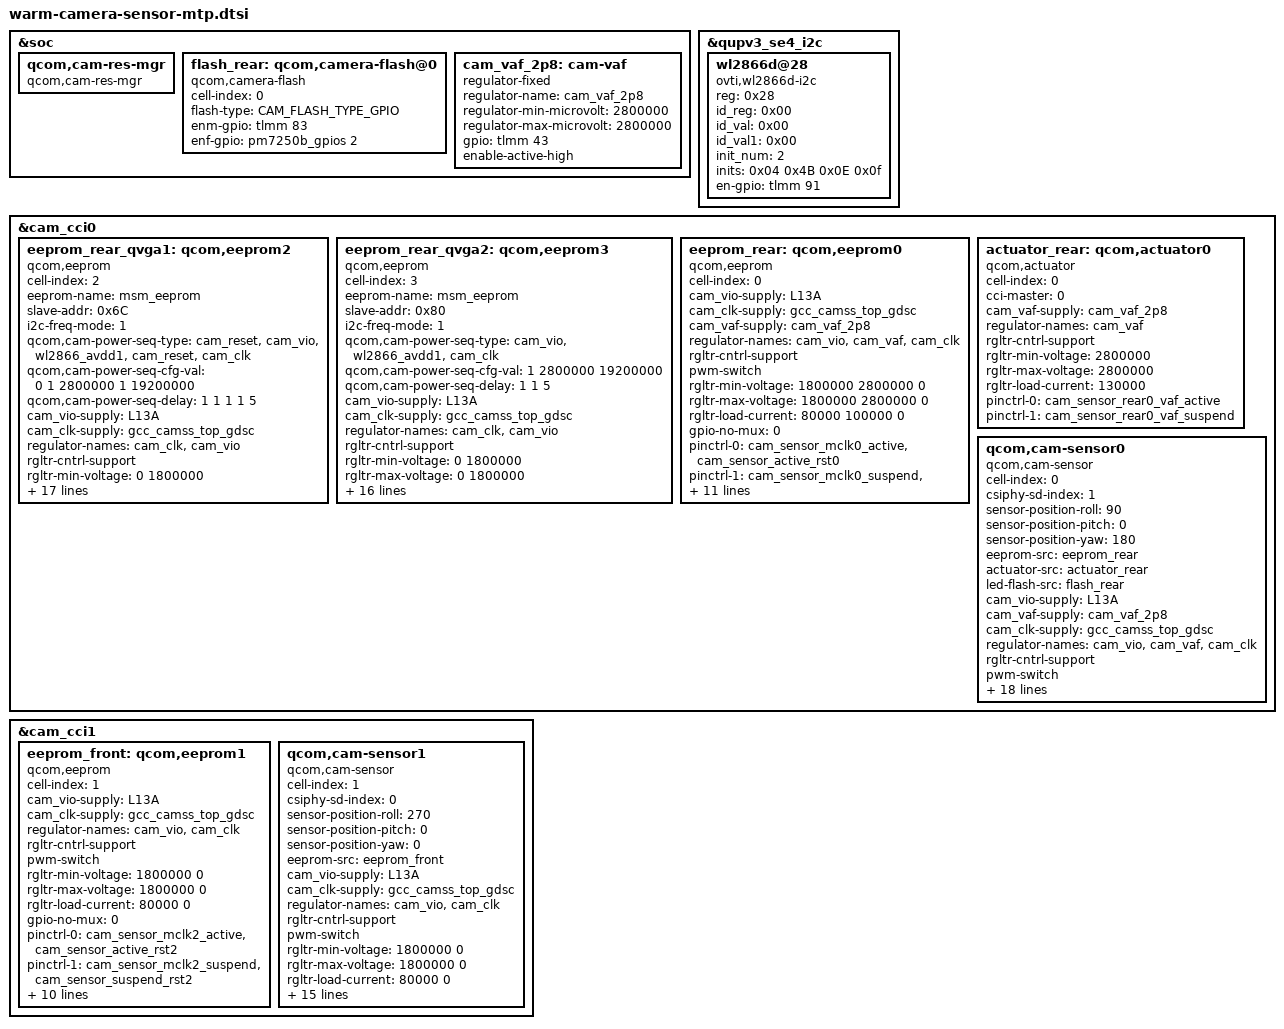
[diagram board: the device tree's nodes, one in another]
#include <dt-bindings/msm-camera.h>
#include <dt-bindings/clock/qcom,gcc-pitti.h>

&soc {
	qcom,cam-res-mgr {
		compatible = "qcom,cam-res-mgr";
		status = "ok";
	};

	flash_rear:qcom,camera-flash@0 {
		cell-index = <0>;
		compatible = "qcom,camera-flash";
		flash-type = <CAM_FLASH_TYPE_GPIO>;
		enm-gpio = <&tlmm 83 0>;
		enf-gpio = <&pm7250b_gpios 2 0>;
		status = "ok";
	};

	cam_vaf_2p8: cam-vaf {
		compatible = "regulator-fixed";
		regulator-name = "cam_vaf_2p8";
		regulator-min-microvolt = <2800000>;
		regulator-max-microvolt = <2800000>;
		gpio = <&tlmm 43 0>;
		enable-active-high;
		status = "okay";
	};
};

&qupv3_se4_i2c {
	status = "ok";
	/*qcom,clk-freq-out = <100000>;*/
	wl2866d@28 {
		compatible = "ovti,wl2866d-i2c";
		reg = <0x28>;
		id_reg = <0x00>;
		id_val = <0x00>;
		id_val1 = <0x00>;
		init_num = <2>;
		inits = <0x04 0x4B 0x0E 0x0f>;
		en-gpio = <&tlmm 91 0>;
		//iov-gpio = <&tlmm 54 0>;
		status = "ok";
	};
};

&cam_cci0 {
	eeprom_rear_qvga1: qcom,eeprom2 {
		cell-index = <2>;
		compatible = "qcom,eeprom";
		eeprom-name = "msm_eeprom";
		slave-addr = <0x6C>;
		i2c-freq-mode = <1>;
		qcom,cam-power-seq-type = "cam_reset", "cam_vio", "wl2866_avdd1", "cam_reset", "cam_clk";
		qcom,cam-power-seq-cfg-val = <0 1 2800000 1 19200000>;
		qcom,cam-power-seq-delay = <1 1 1 1 5>;
		cam_vio-supply = <&L13A>;
		cam_clk-supply = <&gcc_camss_top_gdsc>;
		regulator-names =  "cam_clk", "cam_vio";
		rgltr-cntrl-support;
		rgltr-min-voltage = <0 1800000>;
		rgltr-max-voltage = <0 1800000>;
		rgltr-load-current = <0 80000>;
		gpio-no-mux = <0>;
		pinctrl-names = "cam_default", "cam_suspend";
		pinctrl-0 = <&cam_sensor_mclk1_active
		&cam_sensor_active_rst1>;
		pinctrl-1 = <&cam_sensor_mclk1_suspend
		&cam_sensor_suspend_rst1>;
		gpios = <&tlmm 25 0>,
				<&tlmm 28 0>;
		gpio-reset = <1>;
		gpio-req-tbl-num = <0 1>;
		gpio-req-tbl-flags = <1 0>;
		gpio-req-tbl-label = "CAMIF_MCLK1",
			"CAM_RESET1";
		sensor-mode = <0>;
		cci-master = <1>;
		clocks = <&gcc GCC_CAMSS_MCLK1_CLK>;
		clock-names = "cam_clk";
		clock-cntl-level = "nominal";
		clock-rates = <19200000>;
		status = "ok";
	};

	eeprom_rear_qvga2: qcom,eeprom3 {
		cell-index = <3>;
		compatible = "qcom,eeprom";
		eeprom-name = "msm_eeprom";
		slave-addr = <0x80>;
		i2c-freq-mode = <1>;
		qcom,cam-power-seq-type = "cam_vio", "wl2866_avdd1", "cam_clk";
		qcom,cam-power-seq-cfg-val = < 1 2800000 19200000>;
		qcom,cam-power-seq-delay = < 1 1 5>;
		cam_vio-supply = <&L13A>;
		cam_clk-supply = <&gcc_camss_top_gdsc>;
		regulator-names =  "cam_clk", "cam_vio";
		rgltr-cntrl-support;
		rgltr-min-voltage = <0 1800000>;
		rgltr-max-voltage = <0 1800000>;
		rgltr-load-current = <0 80000>;
		gpio-no-mux = <0>;
		pinctrl-names = "cam_default", "cam_suspend";
		pinctrl-0 = <&cam_sensor_mclk1_active
		&cam_sensor_active_rst1>;
		pinctrl-1 = <&cam_sensor_mclk1_suspend
		&cam_sensor_suspend_rst1>;
		gpios = <&tlmm 25 0>,
				<&tlmm 28 0>;
		gpio-reset = <1>;
		gpio-req-tbl-num = <0 1>;
		gpio-req-tbl-flags = <1 0>;
		gpio-req-tbl-label = "CAMIF_MCLK1",
			"CAM_RESET1";
		sensor-mode = <0>;
		cci-master = <1>;
		clocks = <&gcc GCC_CAMSS_MCLK1_CLK>;
		clock-names = "cam_clk";
		clock-cntl-level = "nominal";
		clock-rates = <19200000>;
		status = "ok";
	};

    eeprom_rear: qcom,eeprom0 {
		cell-index = <0>;
		compatible = "qcom,eeprom";
		cam_vio-supply = <&L13A>;
		cam_clk-supply = <&gcc_camss_top_gdsc>;
		cam_vaf-supply = <&cam_vaf_2p8>;
		regulator-names = "cam_vio", "cam_vaf", "cam_clk";
		rgltr-cntrl-support;
		pwm-switch;
		rgltr-min-voltage = <1800000 2800000 0>;
		rgltr-max-voltage = <1800000 2800000 0>;
		rgltr-load-current = <80000 100000 0>;
		gpio-no-mux = <0>;
		pinctrl-names = "cam_default", "cam_suspend";
		pinctrl-0 = <&cam_sensor_mclk0_active
				&cam_sensor_active_rst0>;
		pinctrl-1 = <&cam_sensor_mclk0_suspend
				&cam_sensor_suspend_rst0>;
		gpios = <&tlmm 24 0>,
		    	<&tlmm 27 0>;
		gpio-reset = <1>;
		gpio-req-tbl-num = <0 1>;
		gpio-req-tbl-flags = <1 0>;
		gpio-req-tbl-label = "CAMIF_MCLK0",
					"CAM_RESET0";
		sensor-mode = <0>;
		cci-master = <0>;
		status = "ok";
		clocks = <&gcc GCC_CAMSS_MCLK0_CLK>;
		clock-names = "cam_clk";
		clock-cntl-level = "nominal";
		clock-rates = <19200000>;
	};

	actuator_rear: qcom,actuator0 {
		cell-index = <0>;
		compatible = "qcom,actuator";
		cci-master = <0>;
		cam_vaf-supply = <&cam_vaf_2p8>;
		regulator-names = "cam_vaf";
		rgltr-cntrl-support;
		rgltr-min-voltage = <2800000>;
		rgltr-max-voltage = <2800000>;
		rgltr-load-current = <130000>;
		pinctrl-names = "cam_default", "cam_suspend";
		pinctrl-0 = <&cam_sensor_rear0_vaf_active>;
		pinctrl-1 = <&cam_sensor_rear0_vaf_suspend>;
		status = "ok";
	};

	/*Rear*/
	qcom,cam-sensor0 {
		cell-index = <0>;
		compatible = "qcom,cam-sensor";
		csiphy-sd-index = <1>;
		sensor-position-roll = <90>;
		sensor-position-pitch = <0>;
		sensor-position-yaw = <180>;
		eeprom-src = <&eeprom_rear>;
		actuator-src = <&actuator_rear>;
		led-flash-src = <&flash_rear>;
		cam_vio-supply = <&L13A>;
		cam_vaf-supply = <&cam_vaf_2p8>;
		cam_clk-supply = <&gcc_camss_top_gdsc>;
		regulator-names = "cam_vio", "cam_vaf", "cam_clk";
		rgltr-cntrl-support;
		pwm-switch;
		rgltr-min-voltage = <1800000 2800000 0>;
		rgltr-max-voltage = <1800000 2800000 0>;
		rgltr-load-current = <80000 100000 0>;
		gpio-no-mux = <0>;
		pinctrl-names = "cam_default", "cam_suspend";
		pinctrl-0 = <&cam_sensor_mclk0_active
			&cam_sensor_active_rst0>;
		pinctrl-1 = <&cam_sensor_mclk0_suspend
			&cam_sensor_suspend_rst0>;
		gpios = <&tlmm 24 0>,
		      <&tlmm 27 0>;
		gpio-reset = <1>;
		gpio-req-tbl-num = <0 1>;
		gpio-req-tbl-flags = <1 0>;
		gpio-req-tbl-label = "CAMIF_MCLK0",
			"CAM_RESET0";
		sensor-mode = <0>;
		cci-master = <0>;
		status = "ok";
		clocks = <&gcc GCC_CAMSS_MCLK0_CLK>;
		clock-names = "cam_clk";
		clock-cntl-level = "nominal";
		clock-rates = <19200000>;
	};
};

&cam_cci1 {
	eeprom_front: qcom,eeprom1 {
		cell-index = <1>;
		compatible = "qcom,eeprom";
		cam_vio-supply = <&L13A>;
		cam_clk-supply = <&gcc_camss_top_gdsc>;
		regulator-names = "cam_vio", "cam_clk";
		rgltr-cntrl-support;
		pwm-switch;
		rgltr-min-voltage = <1800000 0>;
		rgltr-max-voltage = <1800000 0>;
		rgltr-load-current = <80000 0>;
		gpio-no-mux = <0>;
		pinctrl-names = "cam_default", "cam_suspend";
		pinctrl-0 = <&cam_sensor_mclk2_active
				&cam_sensor_active_rst2>;
		pinctrl-1 = <&cam_sensor_mclk2_suspend
				&cam_sensor_suspend_rst2>;
		gpios = <&tlmm 26 0>,
			<&tlmm 29 0>;
		gpio-reset = <1>;
		gpio-req-tbl-num = <0 1>;
		gpio-req-tbl-flags = <1 0>;
		gpio-req-tbl-label = "CAMIF_MCLK2",
					"CAM_RESET2";
		sensor-mode = <0>;
		cci-master = <0>;
		status = "ok";
		clocks = <&gcc GCC_CAMSS_MCLK2_CLK>;
		clock-names = "cam_clk";
		clock-cntl-level = "nominal";
		clock-rates = <19200000>;
	};

	/*Front*/
	qcom,cam-sensor1 {
		cell-index = <1>;
		compatible = "qcom,cam-sensor";
		csiphy-sd-index = <0>;
		sensor-position-roll = <270>;
		sensor-position-pitch = <0>;
		sensor-position-yaw = <0>;
		eeprom-src = <&eeprom_front>;
		cam_vio-supply = <&L13A>;
		cam_clk-supply = <&gcc_camss_top_gdsc>;
		regulator-names = "cam_vio", "cam_clk";
		rgltr-cntrl-support;
		pwm-switch;
		rgltr-min-voltage = <1800000 0>;
		rgltr-max-voltage = <1800000 0>;
		rgltr-load-current = <80000 0>;
		gpio-no-mux = <0>;
		pinctrl-names = "cam_default", "cam_suspend";
		pinctrl-0 = <&cam_sensor_mclk2_active
				&cam_sensor_active_rst2>;
		pinctrl-1 = <&cam_sensor_mclk2_suspend
				&cam_sensor_suspend_rst2>;
		gpios = <&tlmm 26 0>,
			<&tlmm 29 0>;
		gpio-reset = <1>;
		gpio-req-tbl-num = <0 1>;
		gpio-req-tbl-flags = <1 0>;
		gpio-req-tbl-label = "CAMIF_MCLK2",
					"CAM_RESET2";
		sensor-mode = <0>;
		cci-master = <0>;
		status = "ok";
		clocks = <&gcc GCC_CAMSS_MCLK2_CLK>;
		clock-names = "cam_clk";
		clock-cntl-level = "nominal";
		clock-rates = <19200000>;
	};
};
